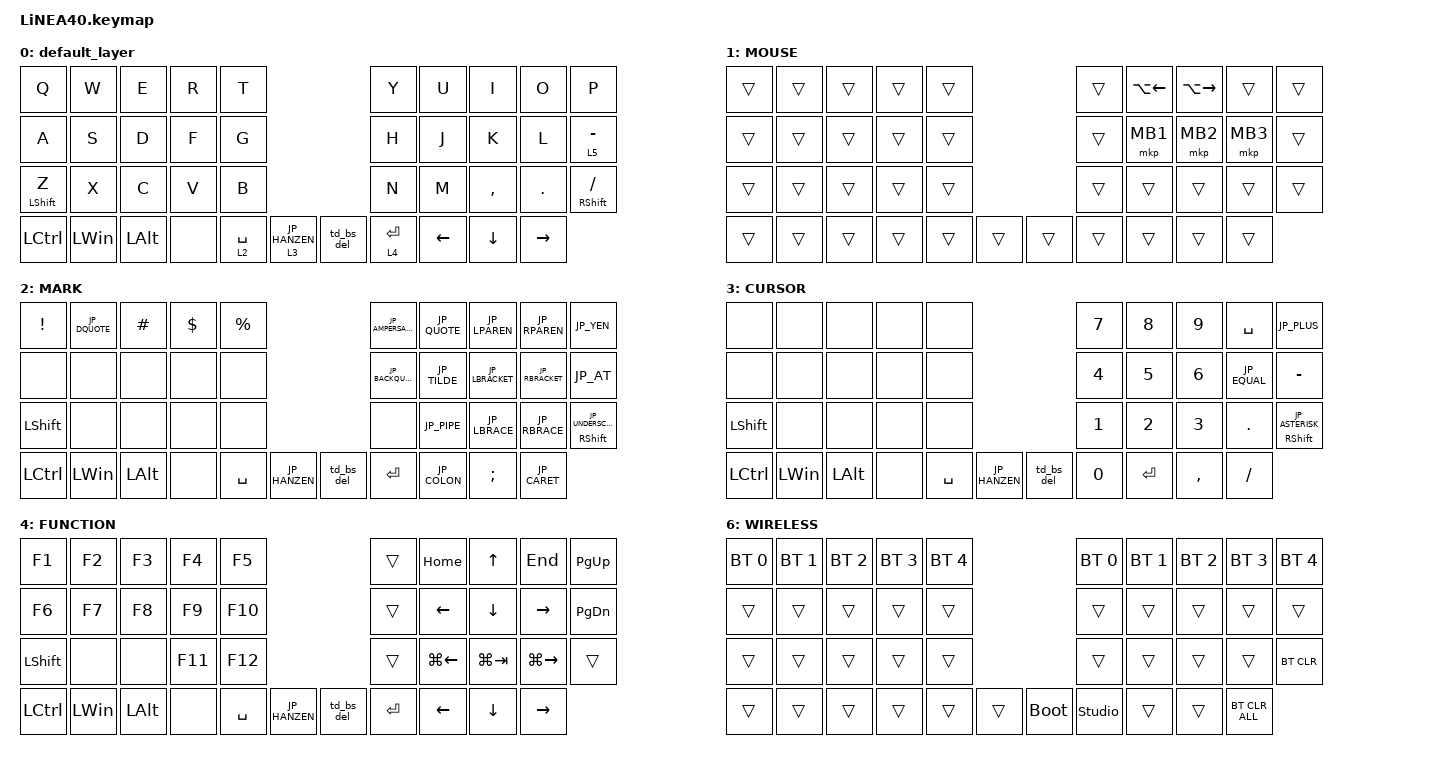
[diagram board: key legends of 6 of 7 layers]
#define ZMK_POINTING_DEFAULT_SCRL_VAL 150

#include <dt-bindings/zmk/input_transform.h>
#include <input/processors.dtsi>
#include <zephyr/dt-bindings/input/input-event-codes.h>
#include <behaviors.dtsi>
#include <dt-bindings/zmk/bt.h>
#include <dt-bindings/zmk/keys.h>
#include <dt-bindings/zmk/pointing.h>

#define MOUSE 1
#define MARK 2
#define CURSOR 3
#define FUNCTION 4
#define SCROLL 5
#define WIRELESS 6

// OS設定を日本語キーボードのまま使用するための変換定義

#define JP_DQUOTE       AT                // "
#define JP_AMPERSAND    CARET             // &
#define JP_QUOTE        AMPERSAND         // '
#define JP_EQUAL        UNDER             // =
#define JP_CARET        EQUAL             // ^
#define JP_YEN          0x89              // ¥
#define JP_PLUS         COLON             // +
#define JP_TILDE        PLUS              // ~
#define JP_PIPE         LS(0x89)          // |
#define JP_AT           LEFT_BRACKET      // @
#define JP_COLON        SINGLE_QUOTE      // :
#define JP_ASTERISK     DOUBLE_QUOTES     // *
#define JP_BACKQUOTE    LEFT_BRACE        // `
#define JP_UNDERSCORE   LS(0x87)          // _
#define JP_LBRACKET     RIGHT_BRACKET     // [
#define JP_RBRACKET     BACKSLASH         // ]
#define JP_LPAREN       ASTERISK          // (
#define JP_RPAREN       LEFT_PARENTHESIS  // )
#define JP_LBRACE       RIGHT_BRACE       // {
#define JP_RBRACE       PIPE              // }
#define JP_KANA         LANGUAGE_1        // かな
#define JP_EISU         LANGUAGE_2        // 英数
#define JP_HANZEN       GRAVE             // 半角/全角

//mouse cursol

&mmv {
    delay-ms = <20>;
    trigger-period-ms = <5>;
    time-to-max-speed-ms = <100>;
    acceleration-exponent = <2>;
};

//mouse scroll

&msc {
    delay-ms = <3>;
    trigger-period-ms = <3>;
    time-to-max-speed-ms = <100>;
    acceleration-exponent = <0>;
};

/ {
    input_processors {
        zip_wheel_scaler: zip_wheel_scaler {
            compatible = "zmk,input-processor-scaler";
            #input-processor-cells = <2>;
            type = <INPUT_EV_REL>;
            codes = <INPUT_REL_WHEEL>;
            track-remainders;
        };
    };
};

&msc_input_listener {
    speed_up {
        layers = <FUNCTION>;
        input-processors = <&zip_wheel_scaler 3 1>; //スクロールを3倍速にする
    };
};

&trackball_listener {
    scroller {
        layers = <SCROLL>;
        input-processors =
            <&zip_xy_transform INPUT_TRANSFORM_Y_INVERT>,
            //スクロール方向を逆転,,,,,,,
            <&zip_xy_to_scroll_mapper>;
    };
};

/ {
    combos {
        compatible = "zmk,combos";

        cmb_esc {
            bindings = <&kp ESC>;
            key-positions = <0 1>;
        };

        cmb_tab {
            bindings = <&kp TAB>;
            key-positions = <10 11>;
        };

        cmb_lshift {
            bindings = <&kp LSHIFT>;
            key-positions = <20 21>;
        };

        cmb_mo_bt {
            bindings = <&mo 6>;
            key-positions = <34 35>;
        };

        cmb_rshift {
            bindings = <&kp RSHIFT>;
            key-positions = <29 28>;
        };

        cmb_mo6 {
            bindings = <&mo 6>;
            key-positions = <36 37>;
        };
    };

    behaviors {
        mt: mod_tap {
            compatible = "zmk,behavior-hold-tap";
            #binding-cells = <2>;
            flavor = "balanced";            // 判定ロジックをbalancedに
            tapping-term-ms = <280>;        // 判定時間
            quick-tap-ms = <175>;           // 連打時はタップを優先
            require-prior-idle-ms = <150>;  // タイピングが止まった時だけホールドを許可
            bindings = <&kp>, <&kp>;
        };

        re_kp: sensor_rotate_kp {
            compatible = "zmk,behavior-sensor-rotate-var";
            #sensor-binding-cells = <2>;
            bindings = <&kp>, <&kp>;
        };

        mouse_scrl: mouse_wheel_scrl {
            compatible = "zmk,behavior-sensor-rotate-var";
            #sensor-binding-cells = <2>;
            bindings = <&msc>, <&msc>;

            tap-ms = <20>;
        };

        td_bs_del: td_bs_del {
            compatible = "zmk,behavior-tap-dance";
            label = "TD_BS_DEL";
            #binding-cells = <0>;
            bindings = <&kp BSPC>, <&kp DELETE>;
        };
    };

    keymap {
        compatible = "zmk,keymap";

        default_layer {
            bindings = <
&kp Q         &kp W         &kp E     &kp R  &kp T                                          &kp Y        &kp U  &kp I      &kp O     &kp P
&kp A         &kp S         &kp D     &kp F  &kp G                                          &kp H        &kp J  &kp K      &kp L     &lt 5 MINUS
&mt LSHIFT Z  &kp X         &kp C     &kp V  &kp B                                          &kp N        &kp M  &kp COMMA  &kp DOT   &mt RSHIFT SLASH
&kp LCTRL     &kp LEFT_WIN  &kp LALT  &none  &lt 2 SPACE  &lt 3 JP_HANZEN    &td_bs_del  &lt 4 ENTER         &kp LEFT   &kp DOWN  &kp RIGHT
            >;

            sensor-bindings = <&mouse_scrl SCRL_DOWN SCRL_UP>;
        };

        //1

        MOUSE {
            bindings = <
&trans  &trans  &trans  &trans  &trans                    &trans  &kp LA(LEFT)  &kp LA(RIGHT)  &trans    &trans
&trans  &trans  &trans  &trans  &trans                    &trans  &mkp MB1      &mkp MB2       &mkp MB3  &trans
&trans  &trans  &trans  &trans  &trans                    &trans  &trans        &trans         &trans    &trans
&trans  &trans  &trans  &trans  &trans  &trans    &trans  &trans                &trans         &trans    &trans
            >;
        };

        //2

        MARK {
            bindings = <
&kp EXCLAMATION  &kp JP_DQUOTE  &kp HASH  &kp DOLLAR  &kp PERCENT                                  &kp JP_AMPERSAND  &kp JP_QUOTE  &kp JP_LPAREN    &kp JP_RPAREN    &kp JP_YEN
&none            &none          &none     &none       &none                                        &kp JP_BACKQUOTE  &kp JP_TILDE  &kp JP_LBRACKET  &kp JP_RBRACKET  &kp JP_AT
&kp LSHIFT       &none          &none     &none       &none                                        &none             &kp JP_PIPE   &kp JP_LBRACE    &kp JP_RBRACE    &mt RSHIFT JP_UNDERSCORE
&kp LCTRL        &kp LEFT_WIN   &kp LALT  &none       &kp SPACE    &kp JP_HANZEN    &td_bs_del  &kp ENTER                       &kp JP_COLON     &kp SEMICOLON    &kp JP_CARET
            >;

            sensor-bindings = <&re_kp C_VOLUME_DOWN C_VOLUME_UP>;
        };

        //3

        CURSOR {
            bindings = <
&none       &none         &none     &none  &none                                      &kp NUMBER_7  &kp NUMBER_8  &kp NUMBER_9  &kp SPACE     &kp JP_PLUS
&none       &none         &none     &none  &none                                      &kp NUMBER_4  &kp NUMBER_5  &kp NUMBER_6  &kp JP_EQUAL  &kp MINUS
&kp LSHIFT  &none         &none     &none  &none                                      &kp NUMBER_1  &kp NUMBER_2  &kp NUMBER_3  &kp DOT       &mt RSHIFT JP_ASTERISK
&kp LCTRL   &kp LEFT_WIN  &kp LALT  &none  &kp SPACE  &kp JP_HANZEN    &td_bs_del  &kp NUMBER_0                &kp ENTER     &kp COMMA     &kp SLASH
            >;
        };

        //4

        FUNCTION {
            bindings = <
&kp F1            &kp F2        &kp F3    &kp F4   &kp F5                                     &trans     &kp HOME      &kp UP       &kp END        &kp PAGE_UP
&kp F6            &kp F7        &kp F8    &kp F9   &kp F10                                    &trans     &kp LEFT      &kp DOWN     &kp RIGHT      &kp PAGE_DOWN
&kp LSHIFT        &none         &none     &kp F11  &kp F12                                    &trans     &kp LG(LEFT)  &kp LG(TAB)  &kp LG(RIGHT)  &trans
&kp LCTRL  &kp LEFT_WIN  &kp LALT  &none    &kp SPACE  &kp JP_HANZEN    &td_bs_del  &kp ENTER                &kp LEFT     &kp DOWN       &kp RIGHT
            >;

            sensor-bindings = <&mouse_scrl SCRL_DOWN SCRL_UP>;
        };

        //5

        SCROLL {
            bindings = <
&trans        &trans        &trans        &trans        &trans                               &trans          &trans        &trans        &trans        &trans
&trans        &trans        &trans        &trans        &trans                               &trans          &trans        &trans        &trans        &trans
&trans        &trans        &trans        &trans        &trans                               &trans          &trans        &trans        &trans        &trans
&trans        &trans        &trans                      &trans     &trans          &trans    &trans                        &trans        &trans        &trans
            >;

            sensor-bindings = <&inc_dec_kp DOWN_ARROW UP_ARROW>;
        };

        //6

        WIRELESS {
            bindings = <
&bt BT_SEL 0  &bt BT_SEL 1  &bt BT_SEL 2  &bt BT_SEL 3  &bt BT_SEL 4                         &bt BT_SEL 0    &bt BT_SEL 1  &bt BT_SEL 2  &bt BT_SEL 3  &bt BT_SEL 4
&trans        &trans        &trans        &trans        &trans                               &trans          &trans        &trans        &trans        &trans
&trans        &trans        &trans        &trans        &trans                               &trans          &trans        &trans        &trans        &bt BT_CLR
&trans        &trans        &trans        &trans        &trans        &trans    &bootloader  &studio_unlock                &trans        &trans        &bt BT_CLR_ALL
            >;

            sensor-bindings = <&inc_dec_kp RIGHT_ARROW LEFT_ARROW>;
        };
    };
};
